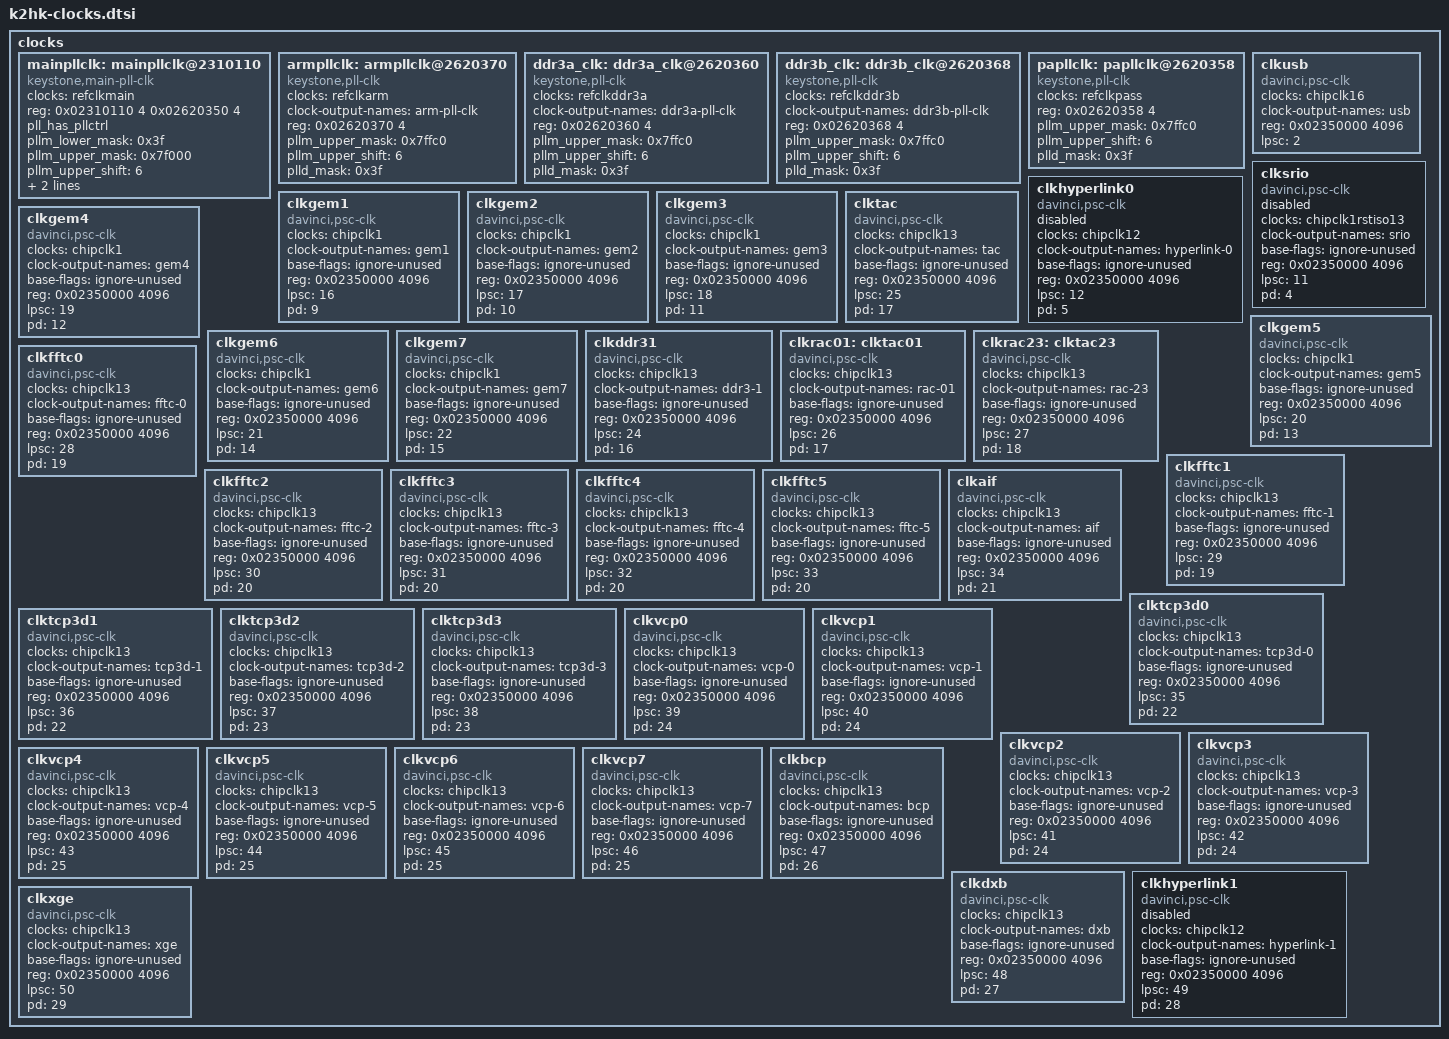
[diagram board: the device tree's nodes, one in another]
/*
 * Copyright 2014 Texas Instruments, Inc.
 *
 * Keystone Hawking/Kepler SoC specific clock driver device bindings
 *
 * This program is free software; you can redistribute it and/or modify
 * it under the terms of the GNU General Public License version 2 as
 * published by the Free Software Foundation.
 */

clocks {
	mainpllclk: mainpllclk@2310110 {
		#clock-cells = <0>;
		compatible = "keystone,main-pll-clk";
		clocks = <&refclkmain>;
		reg = <0x02310110 4	/* PLLCTRL PLLM */
			0x02620350 4>;	/* MAINPLL_CTL0 */
		pll_has_pllctrl;
		pllm_lower_mask	= <0x3f>;
		pllm_upper_mask = <0x7f000>;
		pllm_upper_shift = <6>;
		plld_mask = <0x3f>;
		fixed_postdiv = <2>;
	};

	armpllclk: armpllclk@2620370 {
		#clock-cells = <0>;
		compatible = "keystone,pll-clk";
		clocks = <&refclkarm>;
		clock-output-names = "arm-pll-clk";
		reg = <0x02620370 4>;
		pllm_upper_mask = <0x7ffc0>;
		pllm_upper_shift = <6>;
		plld_mask = <0x3f>;
	};

	ddr3a_clk: ddr3a_clk@2620360 {
		#clock-cells = <0>;
		compatible = "keystone,pll-clk";
		clocks = <&refclkddr3a>;
		clock-output-names = "ddr3a-pll-clk";
		reg = <0x02620360 4>;
		pllm_upper_mask = <0x7ffc0>;
		pllm_upper_shift = <6>;
		plld_mask = <0x3f>;
	};

	ddr3b_clk: ddr3b_clk@2620368 {
		#clock-cells = <0>;
		compatible = "keystone,pll-clk";
		clocks = <&refclkddr3b>;
		clock-output-names = "ddr3b-pll-clk";
		reg = <0x02620368 4>;
		pllm_upper_mask = <0x7ffc0>;
		pllm_upper_shift = <6>;
		plld_mask = <0x3f>;
	};

	papllclk: papllclk@2620358 {
		#clock-cells = <0>;
		compatible = "keystone,pll-clk";
		clocks = <&refclkpass>;
		reg = <0x02620358 4>;	/* PASSPLLCTL0 */
		pllm_upper_mask = <0x7ffc0>;
		pllm_upper_shift = <6>;
		plld_mask = <0x3f>;
	};

	clkusb: clkusb {
		#clock-cells = <0>;
		compatible = "davinci,psc-clk";
		clocks = <&chipclk16>;
		clock-output-names = "usb";
		reg = <0x02350000 4096>;
		lpsc = <2>;
	};

	clksrio: clksrio {
		#clock-cells = <0>;
		compatible = "davinci,psc-clk";
		clocks = <&chipclk1rstiso13>;
		clock-output-names = "srio";
		base-flags = "ignore-unused";
		status = "disabled";
		reg = <0x02350000 4096>;
		lpsc = <11>;
		pd = <4>;
	};

	clkhyperlink0: clkhyperlink0 {
		#clock-cells = <0>;
		compatible = "davinci,psc-clk";
		clocks = <&chipclk12>;
		clock-output-names = "hyperlink-0";
		base-flags = "ignore-unused";
		status = "disabled";
		reg = <0x02350000 4096>;
		lpsc = <12>;
		pd = <5>;
	};

	clkgem1: clkgem1 {
		#clock-cells = <0>;
		compatible = "davinci,psc-clk";
		clocks = <&chipclk1>;
		clock-output-names = "gem1";
		base-flags = "ignore-unused";
		reg = <0x02350000 4096>;
		lpsc = <16>;
		pd = <9>;
	};

	clkgem2: clkgem2 {
		#clock-cells = <0>;
		compatible = "davinci,psc-clk";
		clocks = <&chipclk1>;
		clock-output-names = "gem2";
		base-flags = "ignore-unused";
		reg = <0x02350000 4096>;
		lpsc = <17>;
		pd = <10>;
	};

	clkgem3: clkgem3 {
		#clock-cells = <0>;
		compatible = "davinci,psc-clk";
		clocks = <&chipclk1>;
		clock-output-names = "gem3";
		base-flags = "ignore-unused";
		reg = <0x02350000 4096>;
		lpsc = <18>;
		pd = <11>;
	};

	clkgem4: clkgem4 {
		#clock-cells = <0>;
		compatible = "davinci,psc-clk";
		clocks = <&chipclk1>;
		clock-output-names = "gem4";
		base-flags = "ignore-unused";
		reg = <0x02350000 4096>;
		lpsc = <19>;
		pd = <12>;
	};

	clkgem5: clkgem5 {
		#clock-cells = <0>;
		compatible = "davinci,psc-clk";
		clocks = <&chipclk1>;
		clock-output-names = "gem5";
		base-flags = "ignore-unused";
		reg = <0x02350000 4096>;
		lpsc = <20>;
		pd = <13>;
	};

	clkgem6: clkgem6 {
		#clock-cells = <0>;
		compatible = "davinci,psc-clk";
		clocks = <&chipclk1>;
		clock-output-names = "gem6";
		base-flags = "ignore-unused";
		reg = <0x02350000 4096>;
		lpsc = <21>;
		pd = <14>;
	};

	clkgem7: clkgem7 {
		#clock-cells = <0>;
		compatible = "davinci,psc-clk";
		clocks = <&chipclk1>;
		clock-output-names = "gem7";
		base-flags = "ignore-unused";
		reg = <0x02350000 4096>;
		lpsc = <22>;
		pd = <15>;
	};

	clkddr31: clkddr31 {
		#clock-cells = <0>;
		compatible = "davinci,psc-clk";
		clocks = <&chipclk13>;
		clock-output-names = "ddr3-1";
		base-flags = "ignore-unused";
		reg = <0x02350000 4096>;
		lpsc = <24>;
		pd = <16>;
	};

	clktac: clktac {
		#clock-cells = <0>;
		compatible = "davinci,psc-clk";
		clocks = <&chipclk13>;
		clock-output-names = "tac";
		base-flags = "ignore-unused";
		reg = <0x02350000 4096>;
		lpsc = <25>;
		pd = <17>;
	};

	clkrac01: clktac01 {
		#clock-cells = <0>;
		compatible = "davinci,psc-clk";
		clocks = <&chipclk13>;
		clock-output-names = "rac-01";
		base-flags = "ignore-unused";
		reg = <0x02350000 4096>;
		lpsc = <26>;
		pd = <17>;
	};

	clkrac23: clktac23 {
		#clock-cells = <0>;
		compatible = "davinci,psc-clk";
		clocks = <&chipclk13>;
		clock-output-names = "rac-23";
		base-flags = "ignore-unused";
		reg = <0x02350000 4096>;
		lpsc = <27>;
		pd = <18>;
	};

	clkfftc0: clkfftc0 {
		#clock-cells = <0>;
		compatible = "davinci,psc-clk";
		clocks = <&chipclk13>;
		clock-output-names = "fftc-0";
		base-flags = "ignore-unused";
		reg = <0x02350000 4096>;
		lpsc = <28>;
		pd = <19>;
	};

	clkfftc1: clkfftc1 {
		#clock-cells = <0>;
		compatible = "davinci,psc-clk";
		clocks = <&chipclk13>;
		clock-output-names = "fftc-1";
		base-flags = "ignore-unused";
		reg = <0x02350000 4096>;
		lpsc = <29>;
		pd = <19>;
	};

	clkfftc2: clkfftc2 {
		#clock-cells = <0>;
		compatible = "davinci,psc-clk";
		clocks = <&chipclk13>;
		clock-output-names = "fftc-2";
		base-flags = "ignore-unused";
		reg = <0x02350000 4096>;
		lpsc = <30>;
		pd = <20>;
	};

	clkfftc3: clkfftc3 {
		#clock-cells = <0>;
		compatible = "davinci,psc-clk";
		clocks = <&chipclk13>;
		clock-output-names = "fftc-3";
		base-flags = "ignore-unused";
		reg = <0x02350000 4096>;
		lpsc = <31>;
		pd = <20>;
	};

	clkfftc4: clkfftc4 {
		#clock-cells = <0>;
		compatible = "davinci,psc-clk";
		clocks = <&chipclk13>;
		clock-output-names = "fftc-4";
		base-flags = "ignore-unused";
		reg = <0x02350000 4096>;
		lpsc = <32>;
		pd = <20>;
	};

	clkfftc5: clkfftc5 {
		#clock-cells = <0>;
		compatible = "davinci,psc-clk";
		clocks = <&chipclk13>;
		clock-output-names = "fftc-5";
		base-flags = "ignore-unused";
		reg = <0x02350000 4096>;
		lpsc = <33>;
		pd = <20>;
	};

	clkaif: clkaif {
		#clock-cells = <0>;
		compatible = "davinci,psc-clk";
		clocks = <&chipclk13>;
		clock-output-names = "aif";
		base-flags = "ignore-unused";
		reg = <0x02350000 4096>;
		lpsc = <34>;
		pd = <21>;
	};

	clktcp3d0: clktcp3d0 {
		#clock-cells = <0>;
		compatible = "davinci,psc-clk";
		clocks = <&chipclk13>;
		clock-output-names = "tcp3d-0";
		base-flags = "ignore-unused";
		reg = <0x02350000 4096>;
		lpsc = <35>;
		pd = <22>;
	};

	clktcp3d1: clktcp3d1 {
		#clock-cells = <0>;
		compatible = "davinci,psc-clk";
		clocks = <&chipclk13>;
		clock-output-names = "tcp3d-1";
		base-flags = "ignore-unused";
		reg = <0x02350000 4096>;
		lpsc = <36>;
		pd = <22>;
	};

	clktcp3d2: clktcp3d2 {
		#clock-cells = <0>;
		compatible = "davinci,psc-clk";
		clocks = <&chipclk13>;
		clock-output-names = "tcp3d-2";
		base-flags = "ignore-unused";
		reg = <0x02350000 4096>;
		lpsc = <37>;
		pd = <23>;
	};

	clktcp3d3: clktcp3d3 {
		#clock-cells = <0>;
		compatible = "davinci,psc-clk";
		clocks = <&chipclk13>;
		clock-output-names = "tcp3d-3";
		base-flags = "ignore-unused";
		reg = <0x02350000 4096>;
		lpsc = <38>;
		pd = <23>;
	};

	clkvcp0: clkvcp0 {
		#clock-cells = <0>;
		compatible = "davinci,psc-clk";
		clocks = <&chipclk13>;
		clock-output-names = "vcp-0";
		base-flags = "ignore-unused";
		reg = <0x02350000 4096>;
		lpsc = <39>;
		pd = <24>;
	};

	clkvcp1: clkvcp1 {
		#clock-cells = <0>;
		compatible = "davinci,psc-clk";
		clocks = <&chipclk13>;
		clock-output-names = "vcp-1";
		base-flags = "ignore-unused";
		reg = <0x02350000 4096>;
		lpsc = <40>;
		pd = <24>;
	};

	clkvcp2: clkvcp2 {
		#clock-cells = <0>;
		compatible = "davinci,psc-clk";
		clocks = <&chipclk13>;
		clock-output-names = "vcp-2";
		base-flags = "ignore-unused";
		reg = <0x02350000 4096>;
		lpsc = <41>;
		pd = <24>;
	};

	clkvcp3: clkvcp3 {
		#clock-cells = <0>;
		compatible = "davinci,psc-clk";
		clocks = <&chipclk13>;
		clock-output-names = "vcp-3";
		base-flags = "ignore-unused";
		reg = <0x02350000 4096>;
		lpsc = <42>;
		pd = <24>;
	};

	clkvcp4: clkvcp4 {
		#clock-cells = <0>;
		compatible = "davinci,psc-clk";
		clocks = <&chipclk13>;
		clock-output-names = "vcp-4";
		base-flags = "ignore-unused";
		reg = <0x02350000 4096>;
		lpsc = <43>;
		pd = <25>;
	};

	clkvcp5: clkvcp5 {
		#clock-cells = <0>;
		compatible = "davinci,psc-clk";
		clocks = <&chipclk13>;
		clock-output-names = "vcp-5";
		base-flags = "ignore-unused";
		reg = <0x02350000 4096>;
		lpsc = <44>;
		pd = <25>;
	};

	clkvcp6: clkvcp6 {
		#clock-cells = <0>;
		compatible = "davinci,psc-clk";
		clocks = <&chipclk13>;
		clock-output-names = "vcp-6";
		base-flags = "ignore-unused";
		reg = <0x02350000 4096>;
		lpsc = <45>;
		pd = <25>;
	};

	clkvcp7: clkvcp7 {
		#clock-cells = <0>;
		compatible = "davinci,psc-clk";
		clocks = <&chipclk13>;
		clock-output-names = "vcp-7";
		base-flags = "ignore-unused";
		reg = <0x02350000 4096>;
		lpsc = <46>;
		pd = <25>;
	};

	clkbcp: clkbcp {
		#clock-cells = <0>;
		compatible = "davinci,psc-clk";
		clocks = <&chipclk13>;
		clock-output-names = "bcp";
		base-flags = "ignore-unused";
		reg = <0x02350000 4096>;
		lpsc = <47>;
		pd = <26>;
	};

	clkdxb: clkdxb {
		#clock-cells = <0>;
		compatible = "davinci,psc-clk";
		clocks = <&chipclk13>;
		clock-output-names = "dxb";
		base-flags = "ignore-unused";
		reg = <0x02350000 4096>;
		lpsc = <48>;
		pd = <27>;
	};

	clkhyperlink1: clkhyperlink1 {
		#clock-cells = <0>;
		compatible = "davinci,psc-clk";
		clocks = <&chipclk12>;
		clock-output-names = "hyperlink-1";
		base-flags = "ignore-unused";
		status = "disabled";
		reg = <0x02350000 4096>;
		lpsc = <49>;
		pd = <28>;
	};

	clkxge: clkxge {
		#clock-cells = <0>;
		compatible = "davinci,psc-clk";
		clocks = <&chipclk13>;
		clock-output-names = "xge";
		base-flags = "ignore-unused";
		reg = <0x02350000 4096>;
		lpsc = <50>;
		pd = <29>;
	};
};
